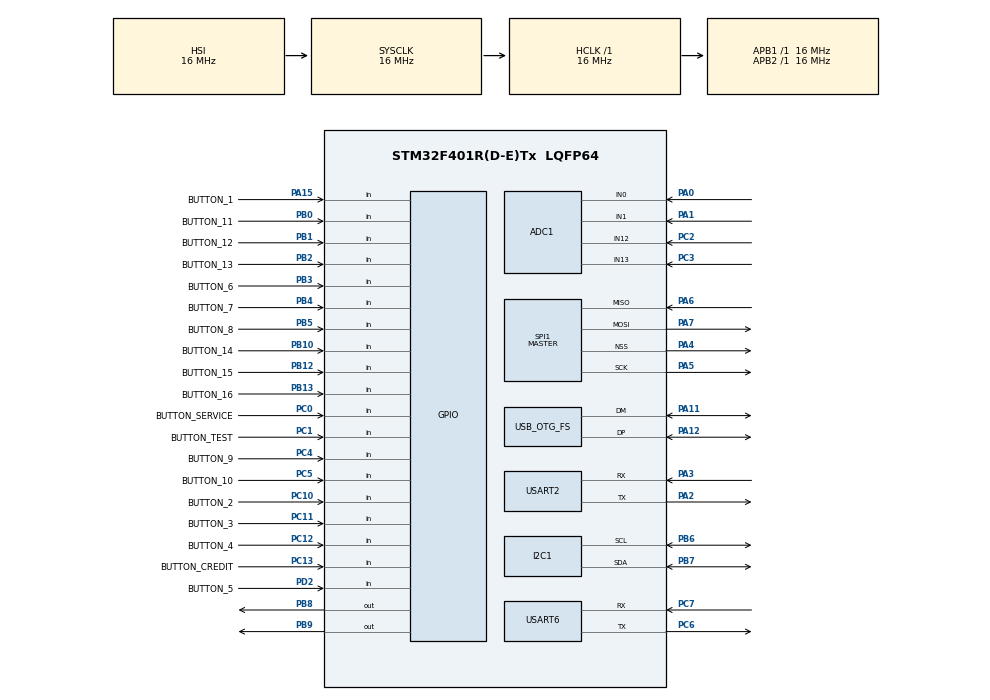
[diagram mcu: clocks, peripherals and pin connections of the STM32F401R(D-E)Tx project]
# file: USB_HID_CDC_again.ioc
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ADC1.Channel-2\#ChannelRegularConversion=ADC_CHANNEL_0
ADC1.NbrOfConversionFlag=1
ADC1.Rank-2\#ChannelRegularConversion=1
ADC1.SamplingTime-2\#ChannelRegularConversion=ADC_SAMPLETIME_3CYCLES
ADC1.master=1
Mcu.Family=STM32F4
Mcu.Name=STM32F401R(D-E)Tx
Mcu.Package=LQFP64
NVIC.OTG_FS_IRQn=true\:0\:0\:false\:false\:true\:false\:true\:true
NVIC.PriorityGroup=NVIC_PRIORITYGROUP_4
PA0-WKUP.Signal=ADCx_IN0
PA1.Signal=ADCx_IN1
PA11.Mode=Device_Only
PA11.Signal=USB_OTG_FS_DM
PA12.Mode=Device_Only
PA12.Signal=USB_OTG_FS_DP
PA13.Mode=Serial_Wire
PA13.Signal=SYS_JTMS-SWDIO
PA14.Mode=Serial_Wire
PA14.Signal=SYS_JTCK-SWCLK
PA15.GPIO_Label=BUTTON_1
PA15.Signal=GPIO_Input
PA2.Mode=Asynchronous
PA2.Signal=USART2_TX
PA3.Mode=Asynchronous
PA3.Signal=USART2_RX
PA4.Mode=NSS_Signal_Hard_Output
PA4.Signal=SPI1_NSS
PA5.Mode=Full_Duplex_Master
PA5.Signal=SPI1_SCK
PA6.Mode=Full_Duplex_Master
PA6.Signal=SPI1_MISO
PA7.Mode=Full_Duplex_Master
PA7.Signal=SPI1_MOSI
PB0.GPIO_Label=BUTTON_11
PB0.Signal=GPIO_Input
PB1.GPIO_Label=BUTTON_12
PB1.Signal=GPIO_Input
PB10.GPIO_Label=BUTTON_14
PB10.Signal=GPIO_Input
PB12.GPIO_Label=BUTTON_15
PB12.Signal=GPIO_Input
PB13.GPIO_Label=BUTTON_16
PB13.Signal=GPIO_Input
PB2.GPIO_Label=BUTTON_13
PB2.Signal=GPIO_Input
PB3.GPIO_Label=BUTTON_6
PB3.Signal=GPIO_Input
PB4.GPIO_Label=BUTTON_7
PB4.Signal=GPIO_Input
PB5.GPIO_Label=BUTTON_8
PB5.Signal=GPIO_Input
PB6.Mode=I2C
PB6.Signal=I2C1_SCL
PB7.Mode=I2C
PB7.Signal=I2C1_SDA
PB8.Signal=GPIO_Output
PB9.Signal=GPIO_Output
PC0.GPIO_Label=BUTTON_SERVICE
PC0.Signal=GPIO_Input
PC1.GPIO_Label=BUTTON_TEST
PC1.Signal=GPIO_Input
PC10.GPIO_Label=BUTTON_2
PC10.Signal=GPIO_Input
PC11.GPIO_Label=BUTTON_3
PC11.Signal=GPIO_Input
PC12.GPIO_Label=BUTTON_4
PC12.Signal=GPIO_Input
PC13-ANTI_TAMP.GPIO_Label=BUTTON_CREDIT
PC13-ANTI_TAMP.Signal=GPIO_Input
PC2.Signal=ADCx_IN12
PC3.Signal=ADCx_IN13
PC4.GPIO_Label=BUTTON_9
PC4.Signal=GPIO_Input
PC5.GPIO_Label=BUTTON_10
PC5.Signal=GPIO_Input
PC6.Mode=Asynchronous
PC6.Signal=USART6_TX
PC7.Mode=Asynchronous
PC7.Signal=USART6_RX
PC8.Signal=S_TIM3_CH3
PC9.Signal=S_TIM3_CH4
PD2.GPIO_Label=BUTTON_5
PD2.Signal=GPIO_Input
PH0\ -\ OSC_IN.Mode=HSE-External-Oscillator
PH0\ -\ OSC_IN.Signal=RCC_OSC_IN
PH1\ -\ OSC_OUT.Mode=HSE-External-Oscillator
PH1\ -\ OSC_OUT.Signal=RCC_OSC_OUT
ProjectManager.HeapSize=0x200
ProjectManager.StackSize=0x400
ProjectManager.TargetToolchain=STM32CubeIDE
RCC.48MHZClocksFreq_Value=48000000
RCC.AHBFreq_Value=16000000
RCC.APB1Freq_Value=16000000
RCC.APB2Freq_Value=16000000
RCC.CortexFreq_Value=16000000
RCC.HSE_VALUE=20000000
RCC.HSI_VALUE=16000000
RCC.LSE_VALUE=32768
RCC.PLLM=10
RCC.PLLN=72
RCC.PLLQ=3
RCC.SYSCLKFreq_VALUE=16000000
RCC.VCOOutputFreq_Value=144000000
SH.ADCx_IN0.0=ADC1_IN0,IN0
SH.ADCx_IN1.0=ADC1_IN1,IN1
SH.ADCx_IN12.0=ADC1_IN12,IN12
SH.ADCx_IN13.0=ADC1_IN13,IN13
SH.S_TIM3_CH3.0=TIM3_CH3
SH.S_TIM3_CH4.0=TIM3_CH4
SPI1.Direction=SPI_DIRECTION_2LINES
SPI1.Mode=SPI_MODE_MASTER
SPI1.VirtualNSS=VM_NSSHARD
SPI1.VirtualType=VM_MASTER
USART2.VirtualMode=VM_ASYNC
USART6.VirtualMode=VM_ASYNC
USB_DEVICE.CLASS_NAME_FS=CDC
USB_DEVICE.PRODUCT_STRING_CDC_FS=Jubeat Controller
USB_DEVICE.USBD_DEBUG_LEVEL-CDC_FS=2
USB_DEVICE.VirtualMode-CDC_FS=Cdc
USB_DEVICE.VirtualModeFS=Cdc_FS
USB_OTG_FS.VirtualMode=Device_Only
USB_OTG_FS.lpm_enable=DISABLE
VP_USB_DEVICE_VS_USB_DEVICE_CDC_FS.Mode=CDC_FS
board=custom

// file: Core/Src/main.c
/* USER CODE BEGIN Header */
/**
  ******************************************************************************
  * @file           : main.c
  * @brief          : Main program body
  ******************************************************************************
  * @attention
  *
  * Copyright (c) 2024 STMicroelectronics.
  * All rights reserved.
  *
  * This software is licensed under terms that can be found in the LICENSE file
  * in the root directory of this software component.
  * If no LICENSE file comes with this software, it is provided AS-IS.
  *
  ******************************************************************************
  */
/* USER CODE END Header */
#include "main.h"
#include "adc.h"
#include "i2c.h"
#include "spi.h"
#include "usart.h"
#include "usb_device.h"
#include "gpio.h"

/* USER CODE BEGIN Includes */
#include "usbd_hid.h"

/* USER CODE END Includes */

void SystemClock_Config(void);

int main(void)
{

  /* MCU Configuration--------------------------------------------------------*/

  /* Reset of all peripherals, Initializes the Flash interface and the Systick. */
  HAL_Init();

  /* Configure the system clock */
  SystemClock_Config();

  /* Initialize all configured peripherals */
  MX_GPIO_Init();
  MX_I2C1_Init();
  MX_SPI1_Init();
  MX_USART2_UART_Init();
  MX_USART6_UART_Init();
  MX_ADC1_Init();
  MX_USB_DEVICE_Init();
  /* USER CODE BEGIN 2 */
  uint8_t report[3]={0};
  extern USBD_HandleTypeDef hUsbDeviceFS;

  USBD_HID_SendReport(&hUsbDeviceFS,report,3);

  /* USER CODE END 2 */

  /* Infinite loop */
  while (1)
  {

    /* USER CODE BEGIN 3 */

	  report[0] = ~report[0];
	  report[1] = ~report[1];
	  report[2] = ~report[2];

	  HAL_Delay(1000);
	  /*if(report[2]==0x08)
	  {
		  report[2] = 0x00;
	  }
	  else
	  {
		  report[2] = 0x08;
	  }*/

	  //report[0] = ~report[0];
	  //report[1] = ~report[1];

	  USBD_HID_SendReport(&hUsbDeviceFS,report,sizeof(report));
}
  /* USER CODE END 3 */
}

void SystemClock_Config(void)
{
  RCC_OscInitTypeDef RCC_OscInitStruct = {0};
  RCC_ClkInitTypeDef RCC_ClkInitStruct = {0};

  /** Configure the main internal regulator output voltage
  */
  __HAL_RCC_PWR_CLK_ENABLE();
  __HAL_PWR_VOLTAGESCALING_CONFIG(PWR_REGULATOR_VOLTAGE_SCALE2);

  /** Initializes the RCC Oscillators according to the specified parameters
  * in the RCC_OscInitTypeDef structure.
  */
  RCC_OscInitStruct.OscillatorType = RCC_OSCILLATORTYPE_HSI|RCC_OSCILLATORTYPE_HSE;
  RCC_OscInitStruct.HSEState = RCC_HSE_ON;
  RCC_OscInitStruct.HSIState = RCC_HSI_ON;
  RCC_OscInitStruct.HSICalibrationValue = RCC_HSICALIBRATION_DEFAULT;
  RCC_OscInitStruct.PLL.PLLState = RCC_PLL_ON;
  RCC_OscInitStruct.PLL.PLLSource = RCC_PLLSOURCE_HSE;
  RCC_OscInitStruct.PLL.PLLM = 10;
  RCC_OscInitStruct.PLL.PLLN = 72;
  RCC_OscInitStruct.PLL.PLLP = RCC_PLLP_DIV2;
  RCC_OscInitStruct.PLL.PLLQ = 3;
  if (HAL_RCC_OscConfig(&RCC_OscInitStruct) != HAL_OK)
  {
    Error_Handler();
  }

  /** Initializes the CPU, AHB and APB buses clocks
  */
  RCC_ClkInitStruct.ClockType = RCC_CLOCKTYPE_HCLK|RCC_CLOCKTYPE_SYSCLK
                              |RCC_CLOCKTYPE_PCLK1|RCC_CLOCKTYPE_PCLK2;
  RCC_ClkInitStruct.SYSCLKSource = RCC_SYSCLKSOURCE_HSI;
  RCC_ClkInitStruct.AHBCLKDivider = RCC_SYSCLK_DIV1;
  RCC_ClkInitStruct.APB1CLKDivider = RCC_HCLK_DIV1;
  RCC_ClkInitStruct.APB2CLKDivider = RCC_HCLK_DIV1;

  if (HAL_RCC_ClockConfig(&RCC_ClkInitStruct, FLASH_LATENCY_0) != HAL_OK)
  {
    Error_Handler();
  }
}

void Error_Handler(void)
{
  __disable_irq();
  while (1)
  {
  }
}
